# AT32M412xx_v2 register map
Vendor: Keil; Series: AT32M412; File version: 1.0
CPU: CM4 r0p1, little endian, no MPU, FPU, 4 interrupt priority bits
Registers are 32-bit, read-write, reset 0x0 unless marked. A register's access mark holds for its fields unless they carry their own. Offsets are from the block's base; [hi:lo] are bit positions.

## CRM — Clock and reset management
Base 0x40023800
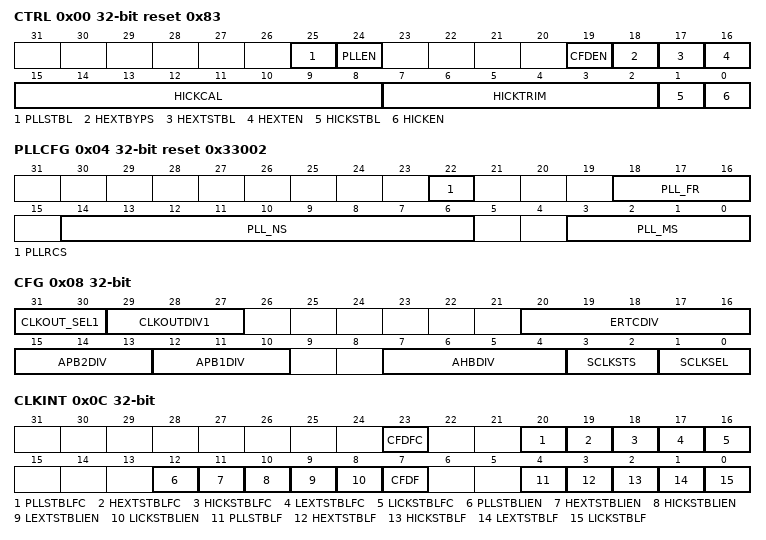
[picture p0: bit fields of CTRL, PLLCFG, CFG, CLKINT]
0x00 CTRL reset 0x83 — Clock control register
  [25] PLLSTBL ro — PLL clock ready flag
  [24] PLLEN — PLL enable
  [19] CFDEN — Clock failure detection enable
  [18] HEXTBYPS — High speed exernal crystal bypass
  [17] HEXTSTBL ro — High speed exernal crystal ready flag
  [16] HEXTEN — High speed exernal crystal enable
  [15:8] HICKCAL ro — High speed internal clock calibration
  [7:2] HICKTRIM — High speed internal clock trimming
  [1] HICKSTBL ro — High speed internal clock ready flag
  [0] HICKEN — High speed internal clock enable
0x04 PLLCFG reset 0x33002 — PLL configuration register (CRM_PLLCFG)
  [22] PLLRCS — PLL reference clock select
  [18:16] PLL_FR — PLL post-division
  [14:6] PLL_NS — PLL frequency multiplication factor
  [3:0] PLL_MS — PLL pre-division
0x08 CFG — Clock configuration register(CRM_CFG)
  [31:30] CLKOUT_SEL1 — Clock output selection1
  [29:27] CLKOUTDIV1 — Clock output division1
  [20:16] ERTCDIV — HEXT division for ERTC clock
  [15:13] APB2DIV — APB2 division
  [12:10] APB1DIV — APB1 division
  [7:4] AHBDIV — AHB division
  [3:2] SCLKSTS ro — System Clock select Status
  [1:0] SCLKSEL — System clock select
0x0C CLKINT — Clock interrupt register (CRM_CLKINT)
  [23] CFDFC wo — Clock failure detection interrupt clear
  [20] PLLSTBLFC wo — PLL ready interrupt clear
  [19] HEXTSTBLFC wo — HEXT ready interrupt clear
  [18] HICKSTBLFC wo — HICK ready interrupt clear
  [17] LEXTSTBLFC wo — LEXT ready interrupt clear
  [16] LICKSTBLFC wo — LICK ready interrupt clear
  [12] PLLSTBLIEN — PLL ready interrupt enable
  [11] HEXTSTBLIEN — HEXT ready interrupt enable
  [10] HICKSTBLIEN — HICK ready interrupt enable
  [9] LEXTSTBLIEN — LEXT ready interrupt enable
  [8] LICKSTBLIEN — LICK ready interrupt enable
  [7] CFDF ro — Clock failure detection interrupt flag
  [4] PLLSTBLF ro — PLL ready interrupt flag
  [3] HEXTSTBLF ro — HEXT ready interrupt flag
  [2] HICKSTBLF ro — HICK ready interrupt flag
  [1] LEXTSTBLF ro — LEXT ready interrupt flag
  [0] LICKSTBLF ro — LICK ready interrupt flag
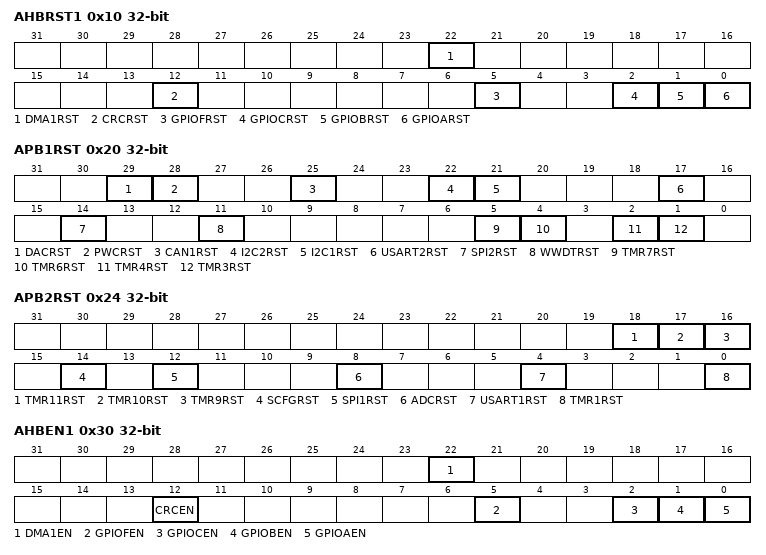
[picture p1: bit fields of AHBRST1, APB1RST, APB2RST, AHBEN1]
0x10 AHBRST1 — AHB peripheral reset register1 (CRM_AHBRST1)
  [22] DMA1RST — DMA1 reset
  [12] CRCRST — CRC reset
  [5] GPIOFRST — IO port F reset
  [2] GPIOCRST — IO port C reset
  [1] GPIOBRST — IO port B reset
  [0] GPIOARST — IO port A reset
0x20 APB1RST — APB1 peripheral reset register (CRM_APB1RST)
  [29] DACRST — DAC reset
  [28] PWCRST — PWC reset
  [25] CAN1RST — CAN1 reset
  [22] I2C2RST — I2C2 reset
  [21] I2C1RST — I2C1 reset
  [17] USART2RST — USART2 reset
  [14] SPI2RST — SPI2 reset
  [11] WWDTRST — Window watchdog reset
  [5] TMR7RST — Timer7 reset
  [4] TMR6RST — Timer6 reset
  [2] TMR4RST — Timer4 reset
  [1] TMR3RST — Timer3 reset
0x24 APB2RST — APB2 peripheral reset register (CRM_APB2RST)
  [18] TMR11RST — Timer 11 reset
  [17] TMR10RST — Timer10 reset
  [16] TMR9RST — Timer9 reset
  [14] SCFGRST — SCFG reset
  [12] SPI1RST — SPI1 reset
  [8] ADCRST — ADC reset
  [4] USART1RST — USART1 reset
  [0] TMR1RST — Timer1 reset
0x30 AHBEN1 — AHB Peripheral Clock enable register 1 (CRM_AHBEN1)
  [22] DMA1EN — DMA1 clock enable
  [12] CRCEN — CRC clock enable
  [5] GPIOFEN — IO F clock enable
  [2] GPIOCEN — IO C clock enable
  [1] GPIOBEN — IO B clock enable
  [0] GPIOAEN — IO A clock enable
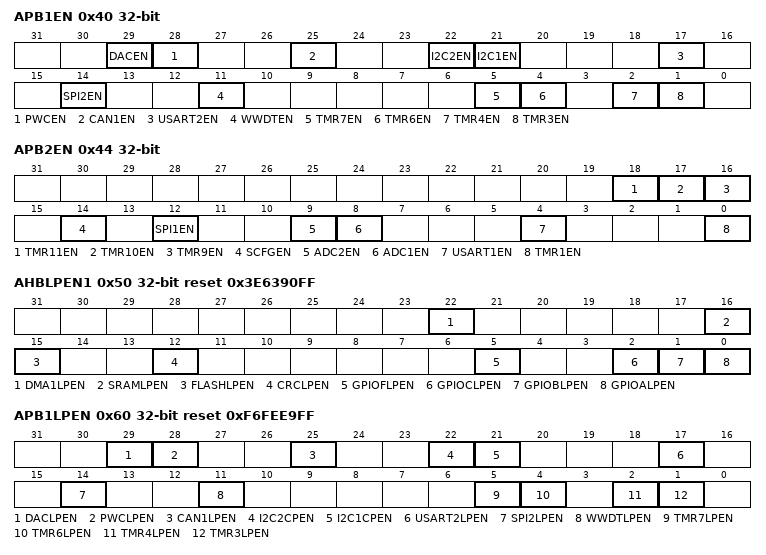
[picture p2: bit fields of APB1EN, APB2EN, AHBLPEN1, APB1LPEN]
0x40 APB1EN — APB1 peripheral clock enable register (CRM_APB1EN)
  [29] DACEN — DAC clock enable
  [28] PWCEN — PWC clock enable
  [25] CAN1EN — CAN1 clock enable
  [22] I2C2EN — I2C2 clock enable
  [21] I2C1EN — I2C1 clock enable
  [17] USART2EN — USART2 clock enable
  [14] SPI2EN — SPI2 clock enable
  [11] WWDTEN — WWDT clock enable
  [5] TMR7EN — Timer7 clock enable
  [4] TMR6EN — Timer6 clock enable
  [2] TMR4EN — Timer4 clock enable
  [1] TMR3EN — Timer3 clock enable
0x44 APB2EN — APB2 peripheral clock enable register (CRM_APB2EN)
  [18] TMR11EN — Timer11 clock enable
  [17] TMR10EN — Timer10 clock enable
  [16] TMR9EN — Timer9 clock enable
  [14] SCFGEN — SCFG clock enable
  [12] SPI1EN — SPI1 clock enable
  [9] ADC2EN — ADC2 clock enable
  [8] ADC1EN — ADC1 clock enable
  [4] USART1EN — USART1 clock enable
  [0] TMR1EN — Timer1 clock enable
0x50 AHBLPEN1 reset 0x3E6390FF — AHB Low-power Peripheral Clock enable register 1 (CRM_AHBLPEN1)
  [22] DMA1LPEN — DMA1 clock enable during sleep mode
  [16] SRAMLPEN — SRAM clock enable during sleep mode
  [15] FLASHLPEN — Flash clock enable during sleep mode
  [12] CRCLPEN — CRC clock enable during sleep mode
  [5] GPIOFLPEN — IO F clock enable during sleep mode
  [2] GPIOCLPEN — IO C clock enable during sleep mode
  [1] GPIOBLPEN — IO B clock enable during sleep mode
  [0] GPIOALPEN — IO A clock enable during sleep mode
0x60 APB1LPEN reset 0xF6FEE9FF — APB1 peripheral Low-power clock enable register (CRM_APB1LPEN)
  [29] DACLPEN — DAC clock enable during sleep mode
  [28] PWCLPEN — PWC clock enable during sleep mode
  [25] CAN1LPEN — CAN1 clock enable during sleep mode
  [22] I2C2CPEN — I2C2 clock enable during sleep mode
  [21] I2C1CPEN — I2C1 clock enable during sleep mode
  [17] USART2LPEN — USART2 clock enable during sleep mode
  [14] SPI2LPEN — SPI2 clock enable during sleep mode
  [11] WWDTLPEN — WWDT clock enable during sleep mode
  [5] TMR7LPEN — Timer7 clock enable during sleep mode
  [4] TMR6LPEN — Timer6 clock enable during sleep mode
  [2] TMR4LPEN — Timer4 clock enable during sleep mode
  [1] TMR3LPEN — Timer3 clock enable during sleep mode
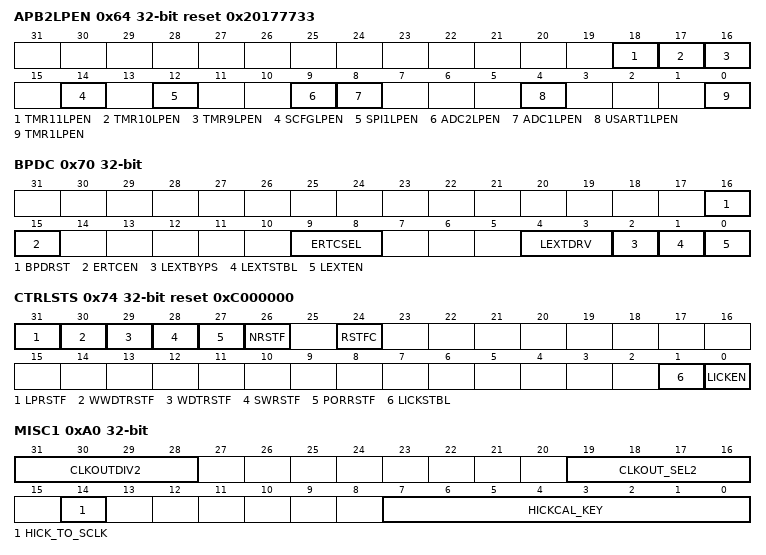
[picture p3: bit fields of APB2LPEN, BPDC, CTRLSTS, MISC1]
0x64 APB2LPEN reset 0x20177733 — APB2 peripheral Low-power clock enable register (CRM_APB2LPEN)
  [18] TMR11LPEN — Timer11 clock enable during sleep mode
  [17] TMR10LPEN — Timer10 clock enable during sleep mode
  [16] TMR9LPEN — Timer9 clock enable during sleep mode
  [14] SCFGLPEN — SCFG clock enable during sleep mode
  [12] SPI1LPEN — SPI1 clock enable during sleep mode
  [9] ADC2LPEN — ADC2 clock enable during sleep mode
  [8] ADC1LPEN — ADC1 clock enable during sleep mode
  [4] USART1LPEN — USART1 clock enable during sleep mode
  [0] TMR1LPEN — Timer1 clock enable during sleep mode
0x68 PICLKS — Peripheral independent clock register (CRM_PICLKS)
  [25:24] CAN1SEL — CAN1 clock select
0x70 BPDC — Battery powered domain control register (CRM_BPDC)
  [16] BPDRST — Battery powered domain software reset
  [15] ERTCEN — ERTC clock enable
  [9:8] ERTCSEL — ERTC clock source selection
  [4:3] LEXTDRV — Low speed external crystal driving strength
  [2] LEXTBYPS — Low speed external crystal bypass
  [1] LEXTSTBL ro — Low speed external crystal ready
  [0] LEXTEN — Low speed external crystal enable
0x74 CTRLSTS reset 0xC000000 — Control/status register (CRM_CTRLSTS)
  [31] LPRSTF — Low-power reset flag
  [30] WWDTRSTF — Window watchdog timer reset flag
  [29] WDTRSTF — Watchdog timer reset flag
  [28] SWRSTF — Software reset flag
  [27] PORRSTF — POR/LVR reset flag
  [26] NRSTF — PIN reset flag
  [24] RSTFC — Reset reset flag
  [1] LICKSTBL ro — Low speed internal clock ready
  [0] LICKEN — Low speed internal clock enable
0xA0 MISC1 — Miscellaneous register1
  [31:28] CLKOUTDIV2 — Clock output division2
  [19:16] CLKOUT_SEL2 — Clock output select2
  [14] HICK_TO_SCLK — HICK to system clock
  [7:0] HICKCAL_KEY — HICKCAL write key value
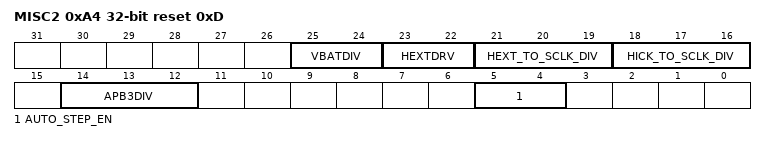
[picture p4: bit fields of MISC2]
0xA4 MISC2 reset 0xD — Miscellaneous register2
  [25:24] VBATDIV — VBAT division
  [23:22] HEXTDRV — HEXT driving strength
  [21:19] HEXT_TO_SCLK_DIV — HEXT as system clock frequency division
  [18:16] HICK_TO_SCLK_DIV — HICK as system clock frequency division
  [14:12] APB3DIV — APB3 division
  [5:4] AUTO_STEP_EN

## Notices in the file
Copyright (C) 2012-2014 ARM Limited. All rights reserved.
Purpose: System Viewer Description (SVD) Example (Schema Version 1.1)
This is a description of a none-existent and incomplete device
for demonstration purposes only.
Redistribution and use in source and binary forms, with or without
modification, are permitted provided that the following conditions are met:
- Redistributions of source code must retain the above copyright
notice, this list of conditions and the following disclaimer.
- Redistributions in binary form must reproduce the above copyright
notice, this list of conditions and the following disclaimer in the
documentation and/or other materials provided with the distribution.
- Neither the name of ARM nor the names of its contributors may be used
to endorse or promote products derived from this software without
specific prior written permission.
THIS SOFTWARE IS PROVIDED BY THE COPYRIGHT HOLDERS AND CONTRIBUTORS "AS IS"
AND ANY EXPRESS OR IMPLIED WARRANTIES, INCLUDING, BUT NOT LIMITED TO, THE
IMPLIED WARRANTIES OF MERCHANTABILITY AND FITNESS FOR A PARTICULAR PURPOSE
ARE DISCLAIMED. IN NO EVENT SHALL COPYRIGHT HOLDERS AND CONTRIBUTORS BE
LIABLE FOR ANY DIRECT, INDIRECT, INCIDENTAL, SPECIAL, EXEMPLARY, OR
CONSEQUENTIAL DAMAGES (INCLUDING, BUT NOT LIMITED TO, PROCUREMENT OF
SUBSTITUTE GOODS OR SERVICES; LOSS OF USE, DATA, OR PROFITS; OR BUSINESS
INTERRUPTION) HOWEVER CAUSED AND ON ANY THEORY OF LIABILITY, WHETHER IN
CONTRACT, STRICT LIABILITY, OR TORT (INCLUDING NEGLIGENCE OR OTHERWISE)
ARISING IN ANY WAY OUT OF THE USE OF THIS SOFTWARE, EVEN IF ADVISED OF THE
POSSIBILITY OF SUCH DAMAGE.
